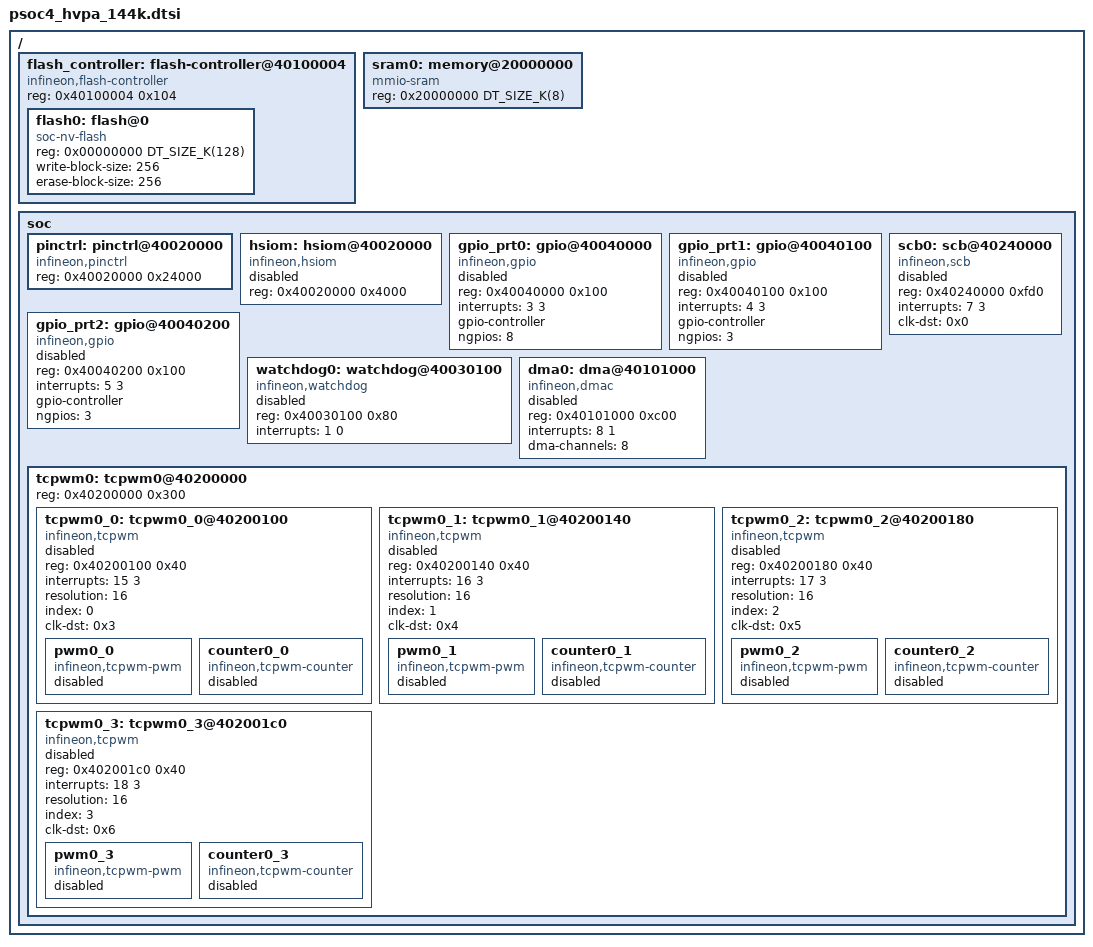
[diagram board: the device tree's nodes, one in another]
/*
 * SPDX-FileCopyrightText: <text>Copyright (c) 2026 Infineon Technologies AG,
 * or an affiliate of Infineon Technologies AG. All rights reserved.</text>
 *
 * SPDX-License-Identifier: Apache-2.0
 */

#include <mem.h>
#include "psoc4_hvpa_144k.cm0p.dtsi"
#include <zephyr/dt-bindings/gpio/gpio.h>

/ {
	flash_controller: flash-controller@40100004 {
		compatible = "infineon,flash-controller";
		reg = <0x40100004 0x104>;
		#address-cells = <1>;
		#size-cells = <1>;
		status = "okay";

		flash0: flash@0 {
			compatible = "soc-nv-flash";
			reg = <0x00000000 DT_SIZE_K(128)>;  /* 128 KB Flash */
			write-block-size = <256>;
			erase-block-size = <256>;
		};
	};

	sram0: memory@20000000 {
		compatible = "mmio-sram";
		reg = <0x20000000 DT_SIZE_K(8)>;  /* 8 KB SRAM */
	};

	soc {
		pinctrl: pinctrl@40020000 {
			compatible = "infineon,pinctrl";
			reg = <0x40020000 0x24000>;
		};

		hsiom: hsiom@40020000 {
			compatible = "infineon,hsiom";
			reg = <0x40020000 0x4000>;
			status = "disabled";
		};

		/* Only ports 0 and 1 are bonded out on the 32-QFN package */
		gpio_prt0: gpio@40040000 {
			compatible = "infineon,gpio";
			reg = <0x40040000 0x100>;
			interrupts = <3 3>;
			gpio-controller;
			ngpios = <8>;
			status = "disabled";
			#gpio-cells = <2>;
		};

		gpio_prt1: gpio@40040100 {
			compatible = "infineon,gpio";
			reg = <0x40040100 0x100>;
			interrupts = <4 3>;
			gpio-controller;
			ngpios = <3>;
			status = "disabled";
			#gpio-cells = <2>;
		};

		gpio_prt2: gpio@40040200 {
			compatible = "infineon,gpio";
			reg = <0x40040200 0x100>;
			interrupts = <5 3>;
			gpio-controller;
			ngpios = <3>;
			status = "disabled";
			#gpio-cells = <2>;
		};

		scb0: scb@40240000 {
			compatible = "infineon,scb";
			reg = <0x40240000 0xfd0>;
			interrupts = <7 3>;
			clk-dst = <0x0>;
			status = "disabled";
		};

		/* WDT_STRUCT is embedded within SRSSHV at offset 0x100 (WDT_SECTION_SIZE = 0x80) */
		watchdog0: watchdog@40030100 {
			compatible = "infineon,watchdog";
			reg = <0x40030100 0x80>;
			interrupts = <1 0>;
			status = "disabled";
		};

		dma0: dma@40101000 {
			#dma-cells = <1>;
			compatible = "infineon,dmac";
			reg = <0x40101000 0xc00>;
			interrupts = <8 1>;
			dma-channels = <8>;
			status = "disabled";
		};

		tcpwm0: tcpwm0@40200000 {
			reg = <0x40200000 0x300>;
			#address-cells = <1>;
			#size-cells = <1>;

			tcpwm0_0: tcpwm0_0@40200100 {
				compatible = "infineon,tcpwm";
				reg = <0x40200100 0x40>;
				interrupts = <15 3>;
				resolution = <16>;
				index = <0>;
				clk-dst = <0x3>;
				status = "disabled";

				pwm0_0: pwm0_0 {
					compatible = "infineon,tcpwm-pwm";
					#pwm-cells = <3>;
					status = "disabled";
				};

				counter0_0: counter0_0 {
					compatible = "infineon,tcpwm-counter";
					status = "disabled";
				};
			};

			tcpwm0_1: tcpwm0_1@40200140 {
				compatible = "infineon,tcpwm";
				reg = <0x40200140 0x40>;
				interrupts = <16 3>;
				resolution = <16>;
				index = <1>;
				clk-dst = <0x4>;
				status = "disabled";

				pwm0_1: pwm0_1 {
					compatible = "infineon,tcpwm-pwm";
					#pwm-cells = <3>;
					status = "disabled";
				};

				counter0_1: counter0_1 {
					compatible = "infineon,tcpwm-counter";
					status = "disabled";
				};
			};

			tcpwm0_2: tcpwm0_2@40200180 {
				compatible = "infineon,tcpwm";
				reg = <0x40200180 0x40>;
				interrupts = <17 3>;
				resolution = <16>;
				index = <2>;
				clk-dst = <0x5>;
				status = "disabled";

				pwm0_2: pwm0_2 {
					compatible = "infineon,tcpwm-pwm";
					#pwm-cells = <3>;
					status = "disabled";
				};

				counter0_2: counter0_2 {
					compatible = "infineon,tcpwm-counter";
					status = "disabled";
				};
			};

			tcpwm0_3: tcpwm0_3@402001c0 {
				compatible = "infineon,tcpwm";
				reg = <0x402001c0 0x40>;
				interrupts = <18 3>;
				resolution = <16>;
				index = <3>;
				clk-dst = <0x6>;
				status = "disabled";

				pwm0_3: pwm0_3 {
					compatible = "infineon,tcpwm-pwm";
					#pwm-cells = <3>;
					status = "disabled";
				};

				counter0_3: counter0_3 {
					compatible = "infineon,tcpwm-counter";
					status = "disabled";
				};
			};
		};
	};
};
